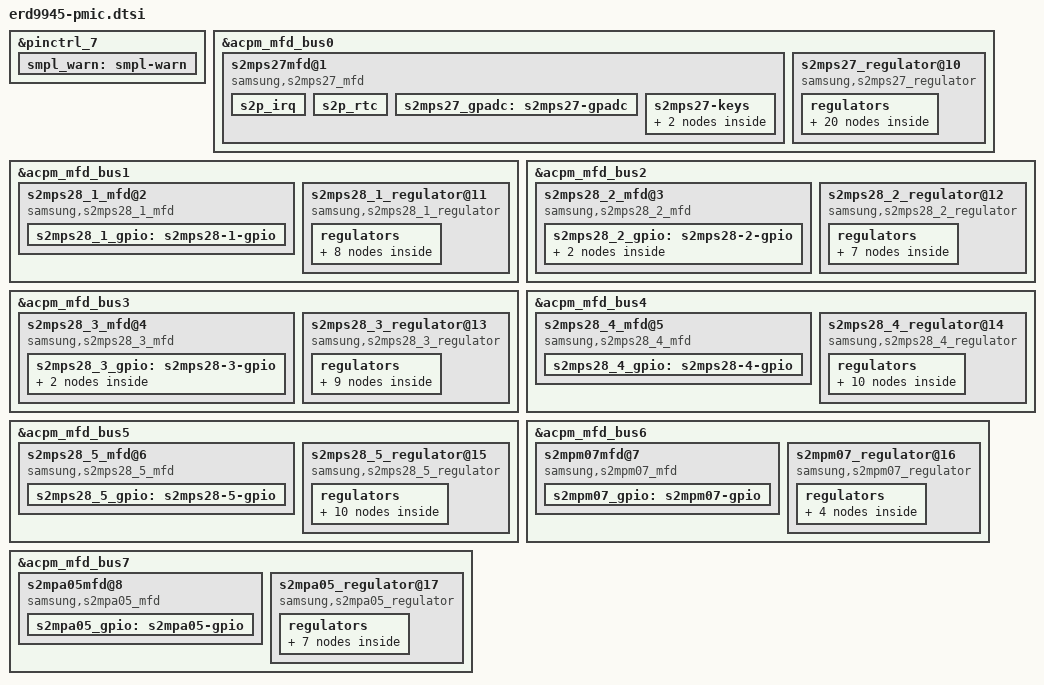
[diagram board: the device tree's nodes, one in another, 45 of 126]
/*
 * SAMSUNG S5E9945 SOC PMIC device tree source
 *
 * Copyright (c) 2023 Samsung Electronics Co., Ltd.
 *             http://www.samsung.com
 *
 * SAMSUNG S5E9945 SOC PMIC device nodes are listed in this file.
 * EXYNOS based board files can include this file and provide
 * values for board specfic bindings.
 *
 * This program is free software; you can redistribute it and/or modify
 * it under the terms of the GNU General Public License version 2 as
 * published by the Free Software Foundation.
 */

&pinctrl_7 {
	smpl_warn: smpl-warn {
		samsung,pins = "gpg3-0";
		samsung,pin-function = <15>;
		samsung,pin-pud = <0>;
		samsung,pin-drv = <0>;
		samsung,pin-con-pdn = <3>;
		samsung,pin-pud-pdn = <0>;
	};
};

&acpm_mfd_bus0 {
	status = "okay";
	#address-cells = <1>;
	#size-cells = <0>;

	s2mps27mfd@1 {
		compatible = "samsung,s2mps27_mfd";
		acpm-ipc-channel = <2>;
		s2p,wakeup = <1>;
		reg = <0x01>;
		sid = <0x0D>;
		pinctrl-names = "default";
		pinctrl-0 = <&smpl_warn>;
		gpios = <&gpg3 0 0>;

		/* SMPL_WARN */
		smpl_warn_en = <1>; /* 1 : enable , 0 : disable */

		s2p_irq {
			interrupts = <GIC_SPI INTREQ__COMB_NONSECURE_INTCOMB_VGPIO2AP IRQ_TYPE_LEVEL_HIGH>;
			interrupt-parent = <&gic>;
			s2p,vgi_cnt = <6>;
			sysreg,spmi_master_pmic = <0x12960000>;
			sysreg,vgpio_monitor = <0>;
			sysreg,vgpio_monitor2 = <4>;
			sysreg,intcomb_vgpio2ap = <0x12930000>;
			sysreg,intcomb_vgpio2pmu = <0x12950000>;
			sysreg,intc0_ipend = <0x0290>;
		};

		s2p_rtc {
			/* wtsr/smpl */
			wtsr_en = <1>; /* 1 : enable, 0 : disable */
			smpl_en = <1>; /* 1 : enable, 0 : disable */
			wtsr_timer_val = <3>;	/* 1000ms */
			smpl_timer_val = <0>;	/* 100ms */
			check_jigon_en = <0>; /* do not check jigon */
			/* If it's first boot,
			   reset rtc to 1/1/2023 12:00:00(Sun) */
			init_time,sec = <0>;
			init_time,min = <0>;
			init_time,hour = <12>;
			init_time,mday = <1>;
			init_time,mon = <0>;
			init_time,year = <123>;
			init_time,wday = <0>;
		};

		s2mps27_gpadc: s2mps27-gpadc {
			#io-channel-cells = <1>;
			io-channel-ranges;
			acpm-ipc-channel = <10>;
		};

	       s2mps27-keys {
			button@1 {
				label = "pmic-keys: KEY_POWER";
				linux,code = <116>;
				wakeup;
			};

			button@2 {
				label = "pmic-keys: KEY_VOLUMEDOWN";
				linux,code = <114>;
			};
		};
	}; /* end of s2mps27mfd@1 */

	s2mps27_regulator@10 {
		compatible = "samsung,s2mps27_regulator";
		acpm-ipc-channel = <2>;
		reg = <0x10>;
		sid = <0x0D>;
		inst_acok_en = <1>; /* 1 : enable , 0 : disable */
		jig_reboot_en = <1>; /* 1 : enable , 0 : disable */

		regulators {
			b1_reg: BUCK_SR1 {
				regulator-name = "vdd_buck_sr1";
				regulator-min-microvolt = <1750000>;
				regulator-max-microvolt = <2000000>;
				regulator-ramp-delay = <6000>;
				regulator-enable-mode = <3>;
				regulator-always-on;
			};

			b_sr1_reg: BUCKB {
				regulator-name = "vdd_buck_boost1";
				regulator-min-microvolt = <3000000>;
				regulator-max-microvolt = <3600000>;
				regulator-ramp-delay = <6000>;
				regulator-enable-mode = <3>;
				regulator-always-on;
			};

			l1_reg: LDO1 {
				regulator-name = "vdd_ldo1";
				regulator-min-microvolt = <1600000>;
				regulator-max-microvolt = <1900000>;
				regulator-ramp-delay = <12000>;
				regulator-enable-mode = <3>;
			};

			l2_reg: LDO2 {
				regulator-name = "vdd_ldo2";
				regulator-min-microvolt = <1600000>;
				regulator-max-microvolt = <1900000>;
				regulator-ramp-delay = <12000>;
				regulator-enable-mode = <1>;
				regulator-always-on;
			};

			l3_reg: LDO3 {
				regulator-name = "vdd_ldo3";
				regulator-min-microvolt = <1600000>;
				regulator-max-microvolt = <1900000>;
				regulator-ramp-delay = <12000>;
				regulator-enable-mode = <3>;
				regulator-always-on;
			};

			l4_reg: LDO4 {
				regulator-name = "vdd_ldo4";
				regulator-min-microvolt = <1600000>;
				regulator-max-microvolt = <1900000>;
				regulator-ramp-delay = <12000>;
				regulator-enable-mode = <3>;
				regulator-always-on;
			};

			l5_reg: LDO5 {
				regulator-name = "vdd_ldo5";
				regulator-min-microvolt = <1600000>;
				regulator-max-microvolt = <1900000>;
				regulator-ramp-delay = <12000>;
				regulator-enable-mode = <3>;
				regulator-always-on;
			};

			l6_reg: LDO6 {
				regulator-name = "vdd_ldo6";
				regulator-min-microvolt = <1800000>;
				regulator-max-microvolt = <1900000>;
				regulator-ramp-delay = <12000>;
				regulator-enable-mode = <3>;
				regulator-always-on;
			};

			l7_reg: LDO7 {
				regulator-name = "vdd18_usb";
				regulator-min-microvolt = <1600000>;
				regulator-max-microvolt = <1900000>;
				regulator-ramp-delay = <12000>;
				regulator-enable-mode = <3>;
				regulator-always-on;
			};

			l8_reg: LDO8 {
				regulator-name = "vdd_ldo8";
				regulator-min-microvolt = <1800000>;
				regulator-max-microvolt = <3375000>;
				regulator-ramp-delay = <12000>;
				regulator-enable-mode = <3>;
			};

			l9_reg: LDO9 {
				regulator-name = "vdd_ldo9";
				regulator-min-microvolt = <1800000>;
				regulator-max-microvolt = <3375000>;
				regulator-ramp-delay = <12000>;
				regulator-enable-mode = <3>;
				regulator-always-on;
			};

			l10_reg: LDO10 {
				regulator-name = "vdd_ldo10";
				regulator-min-microvolt = <1800000>;
				regulator-max-microvolt = <3375000>;
				regulator-ramp-delay = <12000>;
				regulator-enable-mode = <3>;
			};

			l11_reg: LDO11 {
				regulator-name = "vdd33_usb";
				regulator-min-microvolt = <1800000>;
				regulator-max-microvolt = <3375000>;
				regulator-ramp-delay = <12000>;
				regulator-enable-mode = <3>;
				regulator-always-on;
			};

			l12_reg: LDO12 {
				regulator-name = "vdd_ldo12";
				regulator-min-microvolt = <1600000>;
				regulator-max-microvolt = <1900000>;
				regulator-ramp-delay = <12000>;
				regulator-enable-mode = <3>;
				regulator-always-on;
			};

			l13_reg: LDO13 {
				regulator-name = "vdd_ldo13";
				regulator-min-microvolt = <1600000>;
				regulator-max-microvolt = <1900000>;
				regulator-ramp-delay = <12000>;
				regulator-enable-mode = <3>;
			};

			l14_reg: LDO14 {
				regulator-name = "vdd_ldo14";
				regulator-min-microvolt = <1600000>;
				regulator-max-microvolt = <1900000>;
				regulator-ramp-delay = <12000>;
				regulator-enable-mode = <3>;
				regulator-always-on;
			};

			l15_reg: LDO15 {
				regulator-name = "vdd_ldo15";
				regulator-min-microvolt = <1600000>;
				regulator-max-microvolt = <1900000>;
				regulator-ramp-delay = <12000>;
				regulator-enable-mode = <1>;
			};

			l16_reg: LDO16 {
				regulator-name = "vdd_ldo16";
				regulator-min-microvolt = <1600000>;
				regulator-max-microvolt = <1900000>;
				regulator-ramp-delay = <12000>;
				regulator-enable-mode = <3>;
			};

			l17_reg: LDO17 {
				regulator-name = "vdd_ldo17";
				regulator-min-microvolt = <1600000>;
				regulator-max-microvolt = <1900000>;
				regulator-ramp-delay = <12000>;
				regulator-enable-mode = <3>;
				regulator-always-on;
			};

			l18_reg: LDO18 {
				regulator-name = "vdd_ldo18";
				regulator-min-microvolt = <1600000>;
				regulator-max-microvolt = <1900000>;
				regulator-ramp-delay = <12000>;
				regulator-enable-mode = <3>;
				regulator-always-on;
			};
		}; /* end of regulators */
	}; /* end of s2mps27-regulator@10 */
}; /* end of acpm_mfd_bus0 */

&acpm_mfd_bus1 {
	status = "okay";
	#address-cells = <1>;
	#size-cells = <0>;

	s2mps28_1_mfd@2 {
		compatible = "samsung,s2mps28_1_mfd";
		acpm-ipc-channel = <2>;
		s2p,wakeup = <1>;
		reg = <0x02>;
		sid = <0x00>;

		s2mps28_1_gpio: s2mps28-1-gpio {
			gpio-controller;
			#gpio-cells = <2>;
			samsung,npins = <6>;
			status = "okay";
		}; /* s2mps28-1-gpio */
	}; /* end of s2mps28_1_mfd@2 */

	s2mps28_1_regulator@11 {
		compatible = "samsung,s2mps28_1_regulator";
		acpm-ipc-channel = <2>;
		reg = <0x11>;
		sid = <0x00>;
		wtsr_en = <1>; /* 0 : disable, 1: enable */

		regulators {
			s1_b1_reg: BUCK1 {
				regulator-name = "vdd_buck1s";
				regulator-min-microvolt = <400000>;
				regulator-max-microvolt = <1300000>;
				regulator-ramp-delay = <6000>;
				regulator-enable-mode = <1>;
				regulator-always-on;
			};

			s1_b2_reg: BUCK2 {
				regulator-name = "vdd_buck2s";
				regulator-min-microvolt = <400000>;
				regulator-max-microvolt = <1300000>;
				regulator-ramp-delay = <6000>;
				regulator-enable-mode = <1>;
				regulator-always-on;
			};

			s1_b3_reg: BUCK3 {
				regulator-name = "vdd_buck3s";
				regulator-min-microvolt = <400000>;
				regulator-max-microvolt = <1300000>;
				regulator-ramp-delay = <6000>;
				regulator-enable-mode = <1>;
				regulator-always-on;
			};

			s1_b4_reg: BUCK4 {
				regulator-name = "vdd_buck4s";
				regulator-min-microvolt = <400000>;
				regulator-max-microvolt = <1300000>;
				regulator-ramp-delay = <6000>;
				regulator-enable-mode = <1>;
				regulator-always-on;
			};

			s1_b5_reg: BUCK5 {
				regulator-name = "vdd_buck5s";
				regulator-min-microvolt = <400000>;
				regulator-max-microvolt = <1300000>;
				regulator-ramp-delay = <6000>;
				regulator-enable-mode = <1>;
				regulator-always-on;
			};

			s1_b_sr1_reg: BUCK_SR1 {
				regulator-name = "vdd_buck_sr1s";
				regulator-min-microvolt = <600000>;
				regulator-max-microvolt = <1350000>;
				regulator-ramp-delay = <6000>;
				regulator-enable-mode = <3>;
				regulator-always-on;
			};

			s1_l1_reg: LDO1 {
				regulator-name = "vdd_ldo1s";
				regulator-min-microvolt = <400000>;
				regulator-max-microvolt = <1300000>;
				regulator-ramp-delay = <12000>;
				regulator-enable-mode = <3>;
				regulator-always-on;
			};

			s1_l2_reg: LDO2 {
				regulator-name = "vdd_ldo2s";
				regulator-min-microvolt = <400000>;
				regulator-max-microvolt = <1300000>;
				regulator-ramp-delay = <12000>;
				regulator-enable-mode = <1>;
				regulator-always-on;
			};
/*
			s1_l3_reg: LDO3 {
				regulator-name = "vdd_ldo3s";
				regulator-min-microvolt = <400000>;
				regulator-max-microvolt = <1300000>;
				regulator-ramp-delay = <12000>;
				regulator-enable-mode = <3>;
				regulator-always-on;
			};

			s1_l4_reg: LDO4 {
				regulator-name = "vdd_ldo4s";
				regulator-min-microvolt = <400000>;
				regulator-max-microvolt = <1300000>;
				regulator-ramp-delay = <12000>;
				regulator-enable-mode = <3>;
				regulator-always-on;
			};
			// NOT ASSIGNED
			s1_l5_reg: LDO5 {
				regulator-name = "vdd_ldo5s";
				regulator-min-microvolt = <400000>;
				regulator-max-microvolt = <1300000>;
				regulator-ramp-delay = <12000>;
				regulator-enable-mode = <3>;
				regulator-always-on;
			};
*/
		}; /* end of regulators */
	}; /* end of s2mps28_1_regulator@11 */
}; /* end of acpm_mfd_bus1 */

&acpm_mfd_bus2 {
	status = "okay";
	#address-cells = <1>;
	#size-cells = <0>;

	s2mps28_2_mfd@3 {
		compatible = "samsung,s2mps28_2_mfd";
		acpm-ipc-channel = <2>;
		s2p,wakeup = <1>;
		reg = <0x03>;
		sid = <0x03>;

		s2mps28_2_gpio: s2mps28-2-gpio {
			gpio-controller;
			#gpio-cells = <2>;
			samsung,npins = <6>;
			status = "okay";
			pinctrl_cpif: pinctrl-cpif {
				s5100_ap2cp_nreset_n: s5100_ap2cp_nreset_n {
					pins = "gpio_s1";
					pmic-gpio,pull-disable;
				};
			};
		}; /* s2mps28-2-gpio */
	}; /* end of s2mps28_2_mfd@03 */

	s2mps28_2_regulator@12 {
		compatible = "samsung,s2mps28_2_regulator";
		acpm-ipc-channel = <2>;
		reg = <0x12>;
		sid = <0x03>;
		wtsr_en = <1>; /* 0 : disable, 1: enable */

		regulators {
/*
			s2_b1_reg: BUCK1 {
				regulator-name = "vdd_buck1s2";
				regulator-min-microvolt = <400000>;
				regulator-max-microvolt = <1300000>;
				regulator-ramp-delay = <6000>;
				regulator-enable-mode = <3>;
				regulator-always-on;
			};

			s2_b2_reg: BUCK2 {
				regulator-name = "vdd_buck2s2";
				regulator-min-microvolt = <400000>;
				regulator-max-microvolt = <1300000>;
				regulator-ramp-delay = <6000>;
				regulator-enable-mode = <3>;
				regulator-always-on;
			};

			s2_b3_reg: BUCK3 {
				regulator-name = "vdd_buck3s2";
				regulator-min-microvolt = <400000>;
				regulator-max-microvolt = <1300000>;
				regulator-ramp-delay = <6000>;
				regulator-enable-mode = <3>;
				regulator-always-on;
			};
*/
			s2_b4_reg: BUCK4 {
				regulator-name = "vdd_buck4s2";
				regulator-min-microvolt = <400000>;
				regulator-max-microvolt = <1300000>;
				regulator-ramp-delay = <6000>;
				regulator-enable-mode = <1>;
				regulator-always-on;
			};

			s2_b5_reg: BUCK5 {
				regulator-name = "vdd_buck5s2";
				regulator-min-microvolt = <400000>;
				regulator-max-microvolt = <1300000>;
				regulator-ramp-delay = <6000>;
				regulator-enable-mode = <1>;
				regulator-always-on;
			};

			s2_b_sr1_reg: BUCK_SR1 {
				regulator-name = "vdd_buck_sr1s2";
				regulator-min-microvolt = <600000>;
				regulator-max-microvolt = <1350000>;
				regulator-ramp-delay = <6000>;
				regulator-enable-mode = <3>;
				regulator-always-on;
			};
/*
			s2_l1_reg: LDO1 {
				regulator-name = "vdd_ldo1s2";
				regulator-min-microvolt = <400000>;
				regulator-max-microvolt = <1300000>;
				regulator-ramp-delay = <12000>;
				regulator-enable-mode = <3>;
				regulator-always-on;
			};
*/
			s2_l2_reg: LDO2 {
				regulator-name = "vdd_ldo2s2";
				regulator-min-microvolt = <400000>;
				regulator-max-microvolt = <1300000>;
				regulator-ramp-delay = <12000>;
				regulator-enable-mode = <1>;
				regulator-always-on;
			};

			s2_l3_reg: LDO3 {
				regulator-name = "vdd_ldo3s2";
				regulator-min-microvolt = <400000>;
				regulator-max-microvolt = <1300000>;
				regulator-ramp-delay = <12000>;
				regulator-enable-mode = <1>;
				regulator-always-on;
			};

			s2_l4_reg: LDO4 {
				regulator-name = "vdd_ldo4s2";
				regulator-min-microvolt = <400000>;
				regulator-max-microvolt = <1300000>;
				regulator-ramp-delay = <12000>;
				regulator-enable-mode = <1>;
				regulator-always-on;
			};

			s2_l5_reg: LDO5 {
				regulator-name = "vdd_ldo5s2";
				regulator-min-microvolt = <400000>;
				regulator-max-microvolt = <1300000>;
				regulator-ramp-delay = <12000>;
				regulator-enable-mode = <1>;
				regulator-always-on;
			};
		}; /* end of regulators */
	}; /* end of s2mps28_2_regulator@12 */
}; /* end of acpm_mfd_bus2 */

&acpm_mfd_bus3 {
	status = "okay";
	#address-cells = <1>;
	#size-cells = <0>;

	s2mps28_3_mfd@4 {
		compatible = "samsung,s2mps28_3_mfd";
		acpm-ipc-channel = <2>;
		s2p,wakeup = <1>;
		reg = <0x04>;
		sid = <0x04>;

		s2mps28_3_gpio: s2mps28-3-gpio {
			gpio-controller;
			#gpio-cells = <2>;
			samsung,npins = <6>;
			status = "okay";

			pinctrl_nfc_ven: pinctrl-nfc-ven {
				pins = "gpio_s2";
				pmic-gpio,pull-disable;
			};

			pinctrl_nfc_firm: pinctrl-nfc-firm {
				pins = "gpio_s1";
				pmic-gpio,pull-disable;
			};
		}; /* s2mps28-3-gpio */
	}; /* end of s2mps28_3_mfd@4 */

	s2mps28_3_regulator@13 {
		compatible = "samsung,s2mps28_3_regulator";
		acpm-ipc-channel = <2>;
		reg = <0x13>;
		sid = <0x04>;
		wtsr_en = <1>; /* 0 : disable, 1: enable */

		regulators {
			s3_b1_reg: BUCK1 {
				regulator-name = "vdd_buck1s3";
				regulator-min-microvolt = <400000>;
				regulator-max-microvolt = <1300000>;
				regulator-ramp-delay = <6000>;
				regulator-enable-mode = <1>;
				regulator-always-on;
			};

			s3_b2_reg: BUCK2 {
				regulator-name = "vdd_buck2s3";
				regulator-min-microvolt = <400000>;
				regulator-max-microvolt = <1300000>;
				regulator-ramp-delay = <6000>;
				regulator-enable-mode = <1>;
				regulator-always-on;
			};

			s3_b3_reg: BUCK3 {
				regulator-name = "vdd_buck3s3";
				regulator-min-microvolt = <400000>;
				regulator-max-microvolt = <1300000>;
				regulator-ramp-delay = <6000>;
				regulator-enable-mode = <1>;
				regulator-always-on;
			};

			s3_b4_reg: BUCK4 {
				regulator-name = "vdd_buck4s3";
				regulator-min-microvolt = <400000>;
				regulator-max-microvolt = <1300000>;
				regulator-ramp-delay = <6000>;
				regulator-enable-mode = <1>;
				regulator-always-on;
			};

			s3_b5_reg: BUCK5 {
				regulator-name = "vdd_buck5s3";
				regulator-min-microvolt = <400000>;
				regulator-max-microvolt = <1300000>;
				regulator-ramp-delay = <6000>;
				regulator-enable-mode = <1>;
				regulator-always-on;
			};

			s3_b_sr1_reg: BUCK_SR1 {
				regulator-name = "vdd_buck_sr1s3";
				regulator-min-microvolt = <600000>;
				regulator-max-microvolt = <1350000>;
				regulator-ramp-delay = <6000>;
				regulator-enable-mode = <3>;
				regulator-always-on;
			};

			s3_l1_reg: LDO1 {
				regulator-name = "vdd_ldo1s3";
				regulator-min-microvolt = <400000>;
				regulator-max-microvolt = <1300000>;
				regulator-ramp-delay = <12000>;
				regulator-enable-mode = <1>;
				regulator-always-on;
			};

			s3_l2_reg: LDO2 {
				regulator-name = "vdd_ldo2s3";
				regulator-min-microvolt = <400000>;
				regulator-max-microvolt = <1300000>;
				regulator-ramp-delay = <12000>;
				regulator-enable-mode = <1>;
				regulator-always-on;
			};

			s3_l3_reg: LDO3 {
				regulator-name = "vdd_ldo3s3";
				regulator-min-microvolt = <400000>;
				regulator-max-microvolt = <1300000>;
				regulator-ramp-delay = <12000>;
				regulator-enable-mode = <1>;
				regulator-always-on;
			};
/*
			s3_l4_reg: LDO4 {
				regulator-name = "vdd_ldo4s3";
				regulator-min-microvolt = <400000>;
				regulator-max-microvolt = <1300000>;
				regulator-ramp-delay = <12000>;
				regulator-enable-mode = <3>;
				regulator-always-on;
			};
			// NOT ASSIGNED
			s3_l5_reg: LDO5 {
				regulator-name = "vdd_ldo5s3";
				regulator-min-microvolt = <400000>;
				regulator-max-microvolt = <1300000>;
				regulator-ramp-delay = <12000>;
				regulator-enable-mode = <3>;
				regulator-always-on;
			};
*/
		}; /* end of regulators */
	}; /* end of s2mps28_3_regulator@13 */
}; /* end of acpm_mfd_bus3 */

&acpm_mfd_bus4 {
	status = "okay";
	#address-cells = <1>;
	#size-cells = <0>;

	s2mps28_4_mfd@5 {
		compatible = "samsung,s2mps28_4_mfd";
		acpm-ipc-channel = <2>;
		s2p,wakeup = <1>;
		reg = <0x05>;
		sid = <0x0B>;

		s2mps28_4_gpio: s2mps28-4-gpio {
			gpio-controller;
			#gpio-cells = <2>;
			samsung,npins = <6>;
			status = "okay";
		}; /* s2mps28-4-gpio */
	}; /* end of s2mps28_4_mfd@5 */

	s2mps28_4_regulator@14 {
		compatible = "samsung,s2mps28_4_regulator";
		acpm-ipc-channel = <2>;
		reg = <0x14>;
		sid = <0x0B>;
		wtsr_en = <1>; /* 0 : disable, 1: enable */

		regulators {
			s4_b1_reg: BUCK1 {
				regulator-name = "vdd_buck1s4";
				regulator-min-microvolt = <400000>;
				regulator-max-microvolt = <1300000>;
				regulator-ramp-delay = <6000>;
				regulator-enable-mode = <1>;
				regulator-always-on;
			};

			s4_b2_reg: BUCK2 {
				regulator-name = "vdd_buck2s4";
				regulator-min-microvolt = <400000>;
				regulator-max-microvolt = <1300000>;
				regulator-ramp-delay = <6000>;
				regulator-enable-mode = <1>;
				regulator-always-on;
			};

			s4_b3_reg: BUCK3 {
				regulator-name = "vdd_buck3s4";
				regulator-min-microvolt = <400000>;
				regulator-max-microvolt = <1300000>;
				regulator-ramp-delay = <6000>;
				regulator-enable-mode = <1>;
				regulator-always-on;
			};

			s4_b4_reg: BUCK4 {
				regulator-name = "vdd_buck4s4";
				regulator-min-microvolt = <400000>;
				regulator-max-microvolt = <1300000>;
				regulator-ramp-delay = <6000>;
				regulator-enable-mode = <1>;
				regulator-always-on;
			};

			s4_b5_reg: BUCK5 {
				regulator-name = "vdd_buck5s4";
				regulator-min-microvolt = <400000>;
				regulator-max-microvolt = <1300000>;
				regulator-ramp-delay = <6000>;
				regulator-enable-mode = <1>;
				regulator-always-on;
			};

			s4_b_sr1_reg: BUCK_SR1 {
				regulator-name = "vdd_buck_sr1s4";
				regulator-min-microvolt = <600000>;
				regulator-max-microvolt = <1350000>;
				regulator-ramp-delay = <6000>;
				regulator-enable-mode = <3>;
				// regulator-always-on;
			};

			s4_l1_reg: LDO1 {
				regulator-name = "vdd_ldo1s4";
				regulator-min-microvolt = <400000>;
				regulator-max-microvolt = <1300000>;
				regulator-ramp-delay = <12000>;
				regulator-enable-mode = <1>;
				regulator-always-on;
			};

			s4_l2_reg: LDO2 {
				regulator-name = "vdd_ldo2s4";
				regulator-min-microvolt = <400000>;
				regulator-max-microvolt = <1300000>;
				regulator-ramp-delay = <12000>;
				regulator-enable-mode = <3>;
				regulator-always-on;
			};
/*			// NOT ASSIGNED
			s4_l3_reg: LDO3 {
				regulator-name = "vdd_ldo3s4";
				regulator-min-microvolt = <400000>;
				regulator-max-microvolt = <1300000>;
				regulator-ramp-delay = <12000>;
				regulator-enable-mode = <3>;
				regulator-always-on;
			};
*/
			s4_l4_reg: LDO4 {
				regulator-name = "vdd12_usb";
				regulator-min-microvolt = <400000>;
				regulator-max-microvolt = <1300000>;
				regulator-ramp-delay = <12000>;
				regulator-enable-mode = <3>;
				regulator-always-on;
			};

			s4_l5_reg: LDO5 {
				regulator-name = "vdd_ldo5s4";
				regulator-min-microvolt = <400000>;
				regulator-max-microvolt = <1300000>;
				regulator-ramp-delay = <12000>;
				regulator-enable-mode = <3>;
			};
		}; /* end of regulators */
	}; /* end of s2mps28_4_regulator@14 */
}; /* end of acpm_mfd_bus4 */

&acpm_mfd_bus5 {
	status = "okay";
	#address-cells = <1>;
	#size-cells = <0>;

	s2mps28_5_mfd@6 {
		compatible = "samsung,s2mps28_5_mfd";
		acpm-ipc-channel = <2>;
		s2p,wakeup = <1>;
		reg = <0x06>;
		sid = <0x0C>;

		s2mps28_5_gpio: s2mps28-5-gpio {
			gpio-controller;
			#gpio-cells = <2>;
			samsung,npins = <6>;
			status = "okay";
		}; /* s2mps28-5-gpio */
	}; /* end of s2mps28_5_mfd@06 */

	s2mps28_5_regulator@15 {
		compatible = "samsung,s2mps28_5_regulator";
		acpm-ipc-channel = <2>;
		reg = <0x15>;
		sid = <0x0C>;
		wtsr_en = <1>; /* 0 : disable, 1: enable */

		regulators {
			s5_b1_reg: BUCK1 {
				regulator-name = "vdd_buck1s5";
				regulator-min-microvolt = <400000>;
				regulator-max-microvolt = <1300000>;
				regulator-ramp-delay = <6000>;
				regulator-enable-mode = <2>;
				regulator-always-on;
			};

			s5_b2_reg: BUCK2 {
				regulator-name = "vdd_buck2s5";
				regulator-min-microvolt = <400000>;
				regulator-max-microvolt = <1300000>;
				regulator-ramp-delay = <6000>;
				regulator-enable-mode = <1>;
				regulator-always-on;
			};

			s5_b3_reg: BUCK3 {
				regulator-name = "vdd_buck3s5";
				regulator-min-microvolt = <400000>;
				regulator-max-microvolt = <1300000>;
				regulator-ramp-delay = <6000>;
				regulator-enable-mode = <1>;
				regulator-always-on;
			};

			s5_b4_reg: BUCK4 {
				regulator-name = "vdd_buck4s5";
				regulator-min-microvolt = <400000>;
				regulator-max-microvolt = <1300000>;
				regulator-ramp-delay = <6000>;
				regulator-enable-mode = <1>;
				regulator-always-on;
			};

			s5_b5_reg: BUCK5 {
				regulator-name = "vdd_buck5s5";
				regulator-min-microvolt = <400000>;
				regulator-max-microvolt = <1300000>;
				regulator-ramp-delay = <6000>;
				regulator-enable-mode = <1>;
				regulator-always-on;
			};

			s5_b_sr1_reg: BUCK_SR1 {
				regulator-name = "vdd__sr1s5";
				regulator-min-microvolt = <600000>;
				regulator-max-microvolt = <1350000>;
				regulator-ramp-delay = <6000>;
				regulator-enable-mode = <3>;
				regulator-always-on;
			};
/*			// NOT ASSIGNED
			s5_l1_reg: LDO1 {
				regulator-name = "vdd_ldo1s5";
				regulator-min-microvolt = <400000>;
				regulator-max-microvolt = <1300000>;
				regulator-ramp-delay = <12000>;
				regulator-enable-mode = <3>;
				regulator-always-on;
			};
*/
			s5_l2_reg: LDO2 {
				regulator-name = "vdd075_usb";
				regulator-min-microvolt = <400000>;
				regulator-max-microvolt = <1300000>;
				regulator-ramp-delay = <12000>;
				regulator-enable-mode = <3>;
				regulator-always-on;
			};

			s5_l3_reg: LDO3 {
				regulator-name = "vdd_ldo3s5";
				regulator-min-microvolt = <400000>;
				regulator-max-microvolt = <1300000>;
				regulator-ramp-delay = <12000>;
				regulator-enable-mode = <3>;
				regulator-always-on;
			};

			s5_l4_reg: LDO4 {
				regulator-name = "vdd_ldo4s5";
				regulator-min-microvolt = <400000>;
				regulator-max-microvolt = <1300000>;
				regulator-ramp-delay = <12000>;
				regulator-enable-mode = <3>;
				regulator-always-on;
			};

			s5_l5_reg: LDO5 {
				regulator-name = "vdd_ldo5s5";
				regulator-min-microvolt = <400000>;
				regulator-max-microvolt = <1300000>;
				regulator-ramp-delay = <12000>;
				regulator-enable-mode = <1>;
				regulator-always-on;
			};
		}; /* end of regulators */
	}; /* end of s2mps28_5_regulator@15 */
}; /* end of acpm_mfd_bus5 */

&acpm_mfd_bus6 {
	status = "okay";
	#address-cells = <1>;
	#size-cells = <0>;

	s2mpm07mfd@7 {
		compatible = "samsung,s2mpm07_mfd";
		acpm-ipc-channel = <2>;
		s2p,wakeup = <1>;
		reg = <0x07>;
		sid = <0x02>;

		/* s2mpm07-gpio */
		s2mpm07_gpio: s2mpm07-gpio {
			gpio-controller;
			#gpio-cells = <2>;
			samsung,npins = <8>;
			status = "okay";
		};
	}; /* end of s2mpm07mfd@7 */

	s2mpm07_regulator@16 {
		compatible = "samsung,s2mpm07_regulator";
		acpm-ipc-channel = <2>;
		reg = <0x16>;
		sid = <0x02>;
		wtsr_en = <1>; /* 0 : disable, 1: enable */

		regulators {
			r_b1_reg: BUCK1 {
				regulator-name = "buck1r";
				regulator-min-microvolt = <400000>;
				regulator-max-microvolt = <1300000>;
				regulator-ramp-delay = <6000>;
				regulator-enable-mode = <3>;
				// regulator-always-on;
			};

			r_b_sr1_reg: BUCK_SR1 {
				regulator-name = "buck_sr1r";
				regulator-min-microvolt = <600000>;
				regulator-max-microvolt = <1350000>;
				regulator-ramp-delay = <6000>;
				regulator-enable-mode = <3>;
				regulator-always-on;
			};
/*
			r_l1_reg: LDO1 {
				regulator-name = "vdd_ldo1r";
				regulator-min-microvolt = <400000>;
				regulator-max-microvolt = <1300000>;
				regulator-ramp-delay = <12000>;
				regulator-enable-mode = <3>;
				regulator-always-on;
			};

			r_l2_reg: LDO2 {
				regulator-name = "vdd_ldo2r";
				regulator-min-microvolt = <400000>;
				regulator-max-microvolt = <1300000>;
				regulator-ramp-delay = <12000>;
				regulator-enable-mode = <3>;
				regulator-always-on;
			};

			r_l3_reg: LDO3 {
				regulator-name = "vdd_ldo3r";
				regulator-min-microvolt = <400000>;
				regulator-max-microvolt = <1300000>;
				regulator-ramp-delay = <12000>;
				regulator-enable-mode = <3>;
				regulator-always-on;
			};

			r_l4_reg: LDO4 {
				regulator-name = "vdd_ldo4r";
				regulator-min-microvolt = <400000>;
				regulator-max-microvolt = <1300000>;
				regulator-ramp-delay = <12000>;
				regulator-enable-mode = <3>;
				regulator-always-on;
			};

			r_l5_reg: LDO5 {
				regulator-name = "vdd_ldo5r";
				regulator-min-microvolt = <400000>;
				regulator-max-microvolt = <1300000>;
				regulator-ramp-delay = <12000>;
				regulator-enable-mode = <3>;
				regulator-always-on;
			};

			r_l6_reg: LDO6 {
				regulator-name = "vdd_ldo6r";
				regulator-min-microvolt = <1600000>;
				regulator-max-microvolt = <1900000>;
				regulator-ramp-delay = <12000>;
				regulator-enable-mode = <3>;
				regulator-always-on;
			};

			r_l7_reg: LDO7 {
				regulator-name = "vdd_ldo7r";
				regulator-min-microvolt = <400000>;
				regulator-max-microvolt = <1300000>;
				regulator-ramp-delay = <12000>;
				regulator-enable-mode = <3>;
				regulator-always-on;
			};

			r_l8_reg: LDO8 {
				regulator-name = "vdd_ldo8r";
				regulator-min-microvolt = <400000>;
				regulator-max-microvolt = <1300000>;
				regulator-ramp-delay = <12000>;
				regulator-enable-mode = <3>;
				regulator-always-on;
			};

			r_l9_reg: LDO9 {
				regulator-name = "vdd_ldo9r";
				regulator-min-microvolt = <400000>;
				regulator-max-microvolt = <1300000>;
				regulator-ramp-delay = <12000>;
				regulator-enable-mode = <3>;
				regulator-always-on;
			};

			r_l10_reg: LDO10 {
				regulator-name = "vdd_ldo10r";
				regulator-min-microvolt = <1600000>;
				regulator-max-microvolt = <1900000>;
				regulator-ramp-delay = <12000>;
				regulator-enable-mode = <3>;
				regulator-always-on;
			};

			r_l11_reg: LDO11 {
				regulator-name = "vdd_ldo11r";
				regulator-min-microvolt = <1800000>;
				regulator-max-microvolt = <3375000>;
				regulator-ramp-delay = <12000>;
				regulator-enable-mode = <3>;
				regulator-always-on;
			};

			r_l12_reg: LDO12 {
				regulator-name = "vdd_ldo12r";
				regulator-min-microvolt = <400000>;
				regulator-max-microvolt = <1300000>;
				regulator-ramp-delay = <12000>;
				regulator-enable-mode = <3>;
				regulator-always-on;
			};

			r_l13_reg: LDO13 {
				regulator-name = "vdd_ldo13r";
				regulator-min-microvolt = <400000>;
				regulator-max-microvolt = <1300000>;
				regulator-ramp-delay = <12000>;
				regulator-enable-mode = <3>;
				regulator-always-on;
			};

			r_l14_reg: LDO14 {
				regulator-name = "vdd_ldo14r";
				regulator-min-microvolt = <400000>;
				regulator-max-microvolt = <1300000>;
				regulator-ramp-delay = <12000>;
				regulator-enable-mode = <3>;
				regulator-always-on;
			};

			r_l15_reg: LDO15 {
				regulator-name = "vdd_ldo15r";
				regulator-min-microvolt = <400000>;
				regulator-max-microvolt = <1300000>;
				regulator-ramp-delay = <12000>;
				regulator-enable-mode = <3>;
				regulator-always-on;
			};

			r_l16_reg: LDO16 {
				regulator-name = "vdd_ldo16r";
				regulator-min-microvolt = <1600000>;
				regulator-max-microvolt = <1900000>;
				regulator-ramp-delay = <12000>;
				regulator-enable-mode = <3>;
				regulator-always-on;
			};

			r_l17_reg: LDO17 {
				regulator-name = "vdd_ldo17r";
				regulator-min-microvolt = <1600000>;
				regulator-max-microvolt = <1900000>;
				regulator-ramp-delay = <12000>;
				regulator-enable-mode = <3>;
				regulator-always-on;
			};
*/
			r_l18_reg: LDO18 {
				regulator-name = "vdd_ldo18r";
				regulator-min-microvolt = <1800000>;
				regulator-max-microvolt = <3375000>;
				regulator-ramp-delay = <12000>;
				regulator-enable-mode = <3>;
				regulator-always-on;
			};

			r_l19_reg: LDO19 {
				regulator-name = "vdd_ldo19r";
				regulator-min-microvolt = <1800000>;
				regulator-max-microvolt = <3375000>;
				regulator-ramp-delay = <12000>;
				regulator-enable-mode = <3>;
				regulator-always-on;
			};
/*
			r_l20_reg: LDO20 {
				regulator-name = "vdd_ldo20r";
				regulator-min-microvolt = <1800000>;
				regulator-max-microvolt = <3375000>;
				regulator-ramp-delay = <12000>;
				regulator-enable-mode = <3>;
				regulator-always-on;
			};

			r_l21_reg: LDO21 {
				regulator-name = "vdd_ldo21r";
				regulator-min-microvolt = <1800000>;
				regulator-max-microvolt = <3375000>;
				regulator-ramp-delay = <12000>;
				regulator-enable-mode = <3>;
				regulator-always-on;
			};
*/
		}; /* end of regulators */
	}; /* end of s2mpm07_regulator@16 */
}; /* end of acpm_mfd_bus6 */

&acpm_mfd_bus7 {
	status = "okay";
	#address-cells = <1>;
	#size-cells = <0>;

	s2mpa05mfd@8 {
		compatible = "samsung,s2mpa05_mfd";
		acpm-ipc-channel = <2>;
		s2p,wakeup = <1>;
		reg = <0x08>;
		sid = <0x01>;

		/* s2mpa05-gpio */
		s2mpa05_gpio: s2mpa05-gpio {
			gpio-controller;
			#gpio-cells = <2>;
			samsung,npins = <2>;
			status = "okay";
		};
	}; /* end of s2mpa05mfd@8 */

	s2mpa05_regulator@17 {
		compatible = "samsung,s2mpa05_regulator";
		acpm-ipc-channel = <2>;
		reg = <0x17>;
		sid = <0x01>;
		wtsr_en = <1>; /* 0 : disable, 1: enable */

		regulators {
			e_b1_reg: BUCK1 {
				regulator-name = "vdd_cam1";
				regulator-min-microvolt = <400000>;
				regulator-max-microvolt = <1300000>;
				regulator-ramp-delay = <6000>;
				regulator-enable-mode = <1>;
				regulator-always-on;
			};

			e_b2_reg: BUCK2 {
				regulator-name = "vdd_cam2";
				regulator-min-microvolt = <400000>;
				regulator-max-microvolt = <1300000>;
				regulator-ramp-delay = <6000>;
				regulator-enable-mode = <1>;
				regulator-always-on;
			};

			e_b3_reg: BUCK3 {
				regulator-name = "vdd_cam3";
				regulator-min-microvolt = <400000>;
				regulator-max-microvolt = <1300000>;
				regulator-ramp-delay = <6000>;
				regulator-enable-mode = <1>;
				regulator-always-on;
			};

			e_b4_reg: BUCK4 {
				regulator-name = "vdd_cam4";
				regulator-min-microvolt = <400000>;
				regulator-max-microvolt = <1300000>;
				regulator-ramp-delay = <6000>;
				regulator-enable-mode = <1>;
				regulator-always-on;
			};

			e_l1_reg: LDO1 {
				regulator-name = "VDDA_2.8V_SUB2";
				regulator-min-microvolt = <2800000>;
				regulator-max-microvolt = <2800000>;
				regulator-ramp-delay = <12000>;
				regulator-enable-mode = <3>;
			};

			e_l2_reg: LDO2 {
				regulator-name = "VDDA_AF_OIS_3.0V_SUB2";
				regulator-min-microvolt = <3000000>;
				regulator-max-microvolt = <3000000>;
				regulator-ramp-delay = <12000>;
				regulator-enable-mode = <3>;
			};

			e_l3_reg: LDO3 {
				regulator-name = "VDDAFOIS_3.0V_SUB2";
				regulator-min-microvolt = <3000000>;
				regulator-max-microvolt = <3000000>;
				regulator-ramp-delay = <12000>;
				regulator-enable-mode = <3>;
			};
/*
			e_l4_reg: LDO4 {
				regulator-name = "vdd_ldo4e";
				regulator-min-microvolt = <400000>;
				regulator-max-microvolt = <1300000>;
				regulator-ramp-delay = <12000>;
				regulator-enable-mode = <3>;
				regulator-always-on;
			};
*/
		}; /* end of regulators */
	}; /* ene of s2mpa05_regulator@17 */
}; /* end of acpm_mfd_bus7 */
